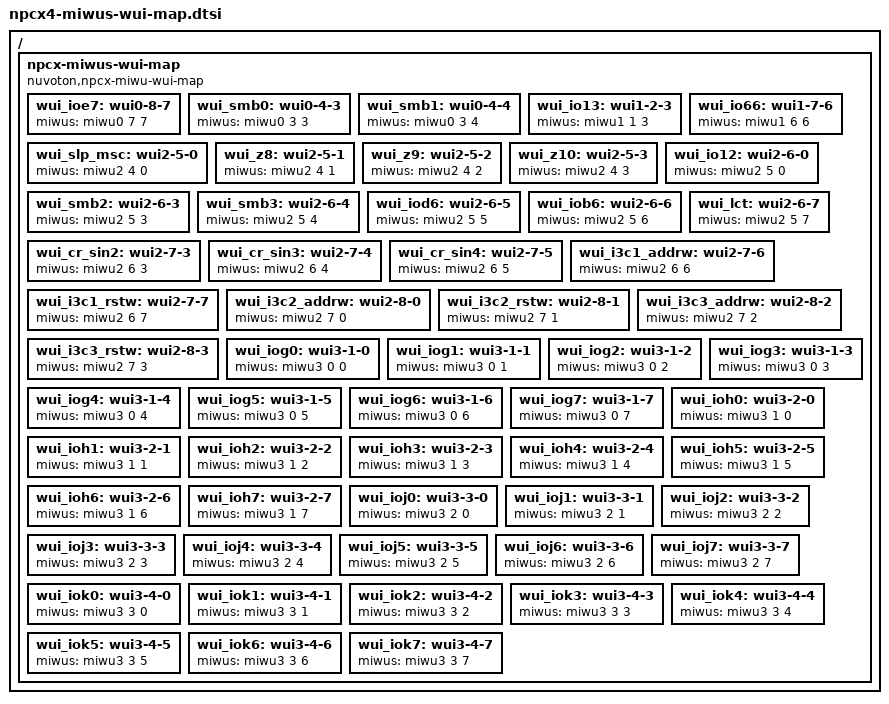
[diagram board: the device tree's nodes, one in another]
/*
 * Copyright (c) 2023 Nuvoton Technology Corporation.
 *
 * SPDX-License-Identifier: Apache-2.0
 */

/* Common Wake-Up Unit Input (WUI) mapping configurations in npcx family */
#include <nuvoton/npcx/npcx-miwus-wui-map.dtsi>

/* Specific Wake-Up Unit Input (WUI) mapping configurations in npcx4 series */
/ {
	/* Mapping between MIWU wui bits and source device */
	npcx-miwus-wui-map {
		compatible = "nuvoton,npcx-miwu-wui-map";

		/* MIWU table 0 */
		/* MIWU group H */
		wui_ioe7: wui0-8-7 {
			miwus = <&miwu0 7 7>; /* GPIOE7 */
		};

		/* MIWU group D */
		wui_smb0: wui0-4-3 {
			miwus = <&miwu0 3 3>; /* SMB0 */
		};

		wui_smb1: wui0-4-4 {
			miwus = <&miwu0 3 4>; /* SMB1 */
		};

		/* MIWU table 1 */
		/* MIWU group B */
		wui_io13: wui1-2-3 {
			miwus = <&miwu1 1 3>; /* GPIO13 */
		};

		/* MIWU group G */
		wui_io66: wui1-7-6 {
			miwus = <&miwu1 6 6>; /* GPIO66 */
		};

		/* MIWU table 2 */
		/* MIWU group E */
		wui_slp_msc: wui2-5-0 {
			miwus = <&miwu2 4 0>; /* SLP_MSC */
		};

		wui_z8: wui2-5-1 {
			miwus = <&miwu2 4 1>; /* Z8 */
		};

		wui_z9: wui2-5-2 {
			miwus = <&miwu2 4 2>; /* Z9 */
		};

		wui_z10: wui2-5-3 {
			miwus = <&miwu2 4 3>; /* Z10 */
		};

		/* MIWU group F */
		wui_io12: wui2-6-0 {
			miwus = <&miwu2 5 0>; /* GPIO12 */
		};

		wui_smb2: wui2-6-3 {
			miwus = <&miwu2 5 3>; /* SMB2 */
		};

		wui_smb3: wui2-6-4 {
			miwus = <&miwu2 5 4>; /* SMB3 */
		};

		wui_iod6: wui2-6-5 {
			miwus = <&miwu2 5 5>; /* GPIOD6 */
		};

		wui_iob6: wui2-6-6 {
			miwus = <&miwu2 5 6>; /* GPIOB6 */
		};

		wui_lct: wui2-6-7 {
			miwus = <&miwu2 5 7>; /* LCT Event */
		};

		/* MIWU group G */
		wui_cr_sin2: wui2-7-3 {
			miwus = <&miwu2 6 3>; /* CR_SIN2 */
		};

		wui_cr_sin3: wui2-7-4 {
			miwus = <&miwu2 6 4>; /* CR_SIN3 */
		};

		wui_cr_sin4: wui2-7-5 {
			miwus = <&miwu2 6 5>; /* CR_SIN4 */
		};

		wui_i3c1_addrw: wui2-7-6 {
			miwus = <&miwu2 6 6>; /* I3C1_ADDRW */
		};

		wui_i3c1_rstw: wui2-7-7 {
			miwus = <&miwu2 6 7>; /* I3C1_RSTW */
		};

		/* MIWU group H */
		wui_i3c2_addrw: wui2-8-0 {
			miwus = <&miwu2 7 0>; /* I3C2_ADDRW */
		};

		wui_i3c2_rstw: wui2-8-1 {
			miwus = <&miwu2 7 1>; /* I3C2_RSTW */
		};

		wui_i3c3_addrw: wui2-8-2 {
			miwus = <&miwu2 7 2>; /* I3C3_ADDRW */
		};

		wui_i3c3_rstw: wui2-8-3 {
			miwus = <&miwu2 7 3>; /* I3C3_RSTW */
		};

		/* MIWU table 3 */
		/* MIWU group A */
		wui_iog0: wui3-1-0 {
			miwus = <&miwu3 0 0>; /* GPIOG0 */
		};

		wui_iog1: wui3-1-1 {
			miwus = <&miwu3 0 1>; /* GPIOG1 */
		};

		wui_iog2: wui3-1-2 {
			miwus = <&miwu3 0 2>; /* GPIOG2 */
		};

		wui_iog3: wui3-1-3 {
			miwus = <&miwu3 0 3>; /* GPIOG3 */
		};

		wui_iog4: wui3-1-4 {
			miwus = <&miwu3 0 4>; /* GPIOG4 */
		};

		wui_iog5: wui3-1-5 {
			miwus = <&miwu3 0 5>; /* GPIOG5 */
		};

		wui_iog6: wui3-1-6 {
			miwus = <&miwu3 0 6>; /* GPIOG6 */
		};

		wui_iog7: wui3-1-7 {
			miwus = <&miwu3 0 7>; /* GPIOG7 */
		};

		/* MIWU group B */
		wui_ioh0: wui3-2-0 {
			miwus = <&miwu3 1 0>; /* GPIOH0 */
		};

		wui_ioh1: wui3-2-1 {
			miwus = <&miwu3 1 1>; /* GPIOH1 */
		};

		wui_ioh2: wui3-2-2 {
			miwus = <&miwu3 1 2>; /* GPIOH2 */
		};

		wui_ioh3: wui3-2-3 {
			miwus = <&miwu3 1 3>; /* GPIOH3 */
		};

		wui_ioh4: wui3-2-4 {
			miwus = <&miwu3 1 4>; /* GPIOH4 */
		};

		wui_ioh5: wui3-2-5 {
			miwus = <&miwu3 1 5>; /* GPIOH5 */
		};

		wui_ioh6: wui3-2-6 {
			miwus = <&miwu3 1 6>; /* GPIOH6 */
		};

		wui_ioh7: wui3-2-7 {
			miwus = <&miwu3 1 7>; /* GPIOH7 */
		};

		/* MIWU group C */
		wui_ioj0: wui3-3-0 {
			miwus = <&miwu3 2 0>; /* GPIOJ0 */
		};

		wui_ioj1: wui3-3-1 {
			miwus = <&miwu3 2 1>; /* GPIOJ1 */
		};

		wui_ioj2: wui3-3-2 {
			miwus = <&miwu3 2 2>; /* GPIOJ2 */
		};

		wui_ioj3: wui3-3-3 {
			miwus = <&miwu3 2 3>; /* GPIOJ3 */
		};

		wui_ioj4: wui3-3-4 {
			miwus = <&miwu3 2 4>; /* GPIOJ4 */
		};

		wui_ioj5: wui3-3-5 {
			miwus = <&miwu3 2 5>; /* GPIOJ5 */
		};

		wui_ioj6: wui3-3-6 {
			miwus = <&miwu3 2 6>; /* GPIOJ6 */
		};

		wui_ioj7: wui3-3-7 {
			miwus = <&miwu3 2 7>; /* GPIOJ7 */
		};

		/* MIWU group D */
		wui_iok0: wui3-4-0 {
			miwus = <&miwu3 3 0>; /* GPIOK0 */
		};

		wui_iok1: wui3-4-1 {
			miwus = <&miwu3 3 1>; /* GPIOK1 */
		};

		wui_iok2: wui3-4-2 {
			miwus = <&miwu3 3 2>; /* GPIOK2 */
		};

		wui_iok3: wui3-4-3 {
			miwus = <&miwu3 3 3>; /* GPIOK3 */
		};

		wui_iok4: wui3-4-4 {
			miwus = <&miwu3 3 4>; /* GPIOK4 */
		};

		wui_iok5: wui3-4-5 {
			miwus = <&miwu3 3 5>; /* GPIOK5 */
		};

		wui_iok6: wui3-4-6 {
			miwus = <&miwu3 3 6>; /* GPIOK6 */
		};

		wui_iok7: wui3-4-7 {
			miwus = <&miwu3 3 7>; /* GPIOK7 */
		};
	};
};
